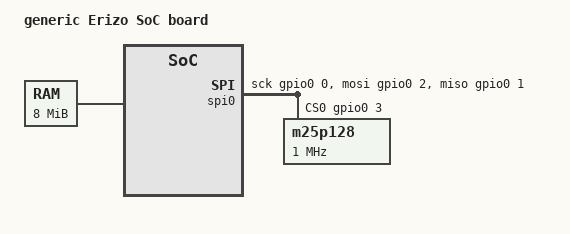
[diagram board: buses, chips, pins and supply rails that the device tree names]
// SPDX-License-Identifier: GPL-2.0-only

#include "erizo.dtsi"
#include <dt-bindings/gpio/gpio.h>

/ {
	model = "generic Erizo SoC board";
	compatible = "miet-riscv-workgroup,erizo-generic-board";

	memory@80000000 {
		device_type = "memory";
		reg = <0x80000000 0x00800000>;
	};

	spi0: spi0 {
		compatible = "spi-gpio";
		#address-cells = <1>;
		#size-cells = <0>;

		gpio-sck  = <&gpio0 0 GPIO_ACTIVE_HIGH>;
		gpio-miso = <&gpio0 1 GPIO_ACTIVE_HIGH>;
		gpio-mosi = <&gpio0 2 GPIO_ACTIVE_HIGH>;
		cs-gpios  = <&gpio0 3 GPIO_ACTIVE_HIGH>;

		num-chipselects = <1>;

		m25p128@0 {
			compatible = "m25p128", "jedec,spi-nor";
			#address-cells = <1>;
			#size-cells = <1>;
			reg = <0>;
			spi-max-frequency = <1000000>;
		};
	};
};
